AUTOSAR XML (schema 00048)
package /AdaptiveApplicationSwComponent
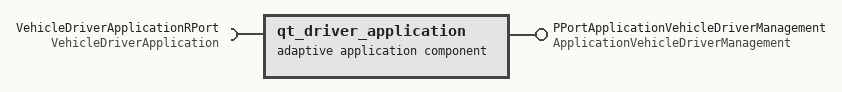
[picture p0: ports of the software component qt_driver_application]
  adaptive application sw component type qt_driver_application
    require port VehicleDriverApplicationRPort: required-interface=VehicleDriverApplication
    provide port PPortApplicationVehicleDriverManagement: provided-interface=ApplicationVehicleDriverManagement
package /Executables
  executable qt_driver_application
    root sw component prototype qt_driver_application_root: application-type=qt_driver_application
package /ProcessDesign
  process design qt_driver_application: executable=qt_driver_application
